AUTOSAR XML (schema 4-0-3)
standard types defined: UInt32, UInt8
package /AUTOSAR_Platform/DataConstrs
  range DC_UInt8: raw 0..255
package /PATAC/MSM/ComponentTypes
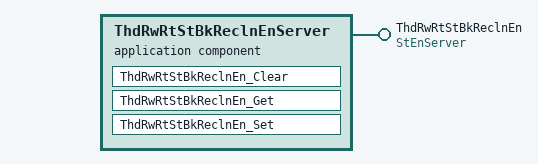
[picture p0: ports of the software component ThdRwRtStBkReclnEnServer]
  application sw component type ThdRwRtStBkReclnEnServer
    provide port ThdRwRtStBkReclnEn: provided-com-specs=[{operation=Clear, queue-length=1}, {operation=Get, queue-length=1}, {operation=Set, queue-length=1}], provided-interface=StEnServer
    behavior ThdRwRtStBkReclnEnServer_InternalBehavior
      operation invoked event OIT_ThdRwRtStBkReclnEn_Clear_ThdRwRtStBkReclnEn_Clear: start-on-event=ThdRwRtStBkReclnEn_Clear, operation=ThdRwRtStBkReclnEn.Clear
      operation invoked event OIT_ThdRwRtStBkReclnEn_Get_ThdRwRtStBkReclnEn_Get: start-on-event=ThdRwRtStBkReclnEn_Get, operation=ThdRwRtStBkReclnEn.Get
      operation invoked event OIT_ThdRwRtStBkReclnEn_Set_ThdRwRtStBkReclnEn_Set: start-on-event=ThdRwRtStBkReclnEn_Set, operation=ThdRwRtStBkReclnEn.Set
      runnable ThdRwRtStBkReclnEn_Clear
      runnable ThdRwRtStBkReclnEn_Get
      runnable ThdRwRtStBkReclnEn_Set
  swc implementation ThdRwRtStBkReclnEnServer_Implementation: behavior=ThdRwRtStBkReclnEnServer_InternalBehavior
    code-descriptors:
      code Default: artifact-descriptors=autosar-engineering-object={short-label=Default, category=SWSRC}
package /PATAC/MSM/ModeAdjust/PortInterface
  client server interface StEnServer
    operation Clear
      arg data: type=UInt8, direction=IN, server-argument-impl-policy=USE-ARGUMENT-TYPE
    operation Get
      arg data: type=UInt32, direction=OUT, server-argument-impl-policy=USE-ARGUMENT-TYPE
    operation Set
      arg data: type=UInt8, direction=IN, server-argument-impl-policy=USE-ARGUMENT-TYPE
